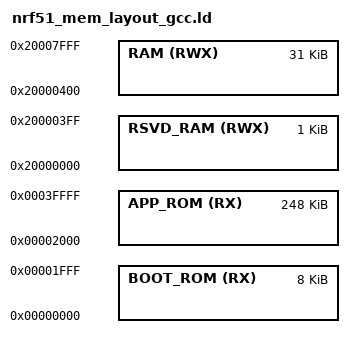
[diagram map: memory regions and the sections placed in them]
/*
 *    0x0000.0000 +----------------------------------------+    -----
 *                |                                        |      ^
 *                |          .system_isr_vectors           |      |
 *                |                                        |      |
 *                +----------------------------------------+      |
 *                |                                        |      |
 *                |           .boot_isr_vectors            |      |
 *                |                                        |      |
 *                +----------------------------------------+      |
 *                |                                        |      |
 *                |                                        |      |
 *                |                                        |      |
 *                |               .boot_text               |      |
 *                |                                        |      |
 *                |                                        |      |
 *                |                                        |      |
 *                +----------------------------------------+      |
 *                |                                        |      |
 *                |            .boot_data (LMA)            |      |
 *                |                                        |      |
 *                +----------------------------------------+      |
 *                |  /  /  /  /  /  /  /  /  /  /  /  /  / |      |
 *                | /  /  /  /  /  RESERVED /  /  /  /  /  |    FLASH
 *                |/  /  /  /  /  /  /  /  /  /  /  /  /  /|      |
 *    0x0000.2000 +----------------------------------------+      |
 *                |                                        |      |
 *                |            .app_isr_vectors            |      |
 *                |                                        |      |
 *                +----------------------------------------+      |
 *                |                                        |      |
 *                |                                        |      |
 *                |                                        |      |
 *                |               .app_text                |      |
 *                |                                        |      |
 *                |                                        |      |
 *                |                                        |      |
 *                +----------------------------------------+      |
 *                |                                        |      |
 *                |            .app_data (LMA)             |      |
 *                |                                        |      |
 *                +----------------------------------------+      |
 *                |  /  /  /  /  /  /  /  /  /  /  /  /  / |      |
 *                | /  /  /  /  /  RESERVED /  /  /  /  /  |      |
 *                |/  /  /  /  /  /  /  /  /  /  /  /  /  /|      v
 *    0x0004.0000 +----------------------------------------+    -----
 *                |  /  /  /  /  /  /  /  /  /  /  /  /  / |
 *                | /  /  /  /  /  RESERVED /  /  /  /  /  |
 *                |/  /  /  /  /  /  /  /  /  /  /  /  /  /|
 *    0x2000.0000 +----------------------------------------+    -----
 *                |              .pseudo_vtor              |      ^
 *    0x2000.0004 +----------------------------------------+      |
 *                |                                        |      |
 *                |              .*_data (VMA)             |      |
 *                |                                        |      |
 *                +----------------------------------------+      |
 *                |                                        |      |
 *                |                 .*_bss                 |      |
 *                |                                        |     RAM
 *                +----------------------------------------+      |
 *                |                                        |      |
 *                |                 .*_heap                |      |
 *                |                                        |      |
 *                +----------------------------------------+      |
 *                |                                        |      |
 *                |                .*_stack                |      |
 *                |                                        |      v
 *    0x2000.8000 +----------------------------------------+    -----
 */


_rom_start     = 0x00000000;
_rom_size      = 0x00040000; /* 256K */
_boot_rom_size = 0x00002000; /*   8K */
_ram_start     = 0x20000000;
_ram_size      = 0x00008000; /*  32K */
_ram_rsvd_size = 0x00000400; /*   1K */

MEMORY
{
    BOOT_ROM (RX)  : ORIGIN = _rom_start,                    LENGTH = _boot_rom_size
    APP_ROM  (RX)  : ORIGIN = (_rom_start + _boot_rom_size), LENGTH = (_rom_size - _boot_rom_size)
    RSVD_RAM (RWX) : ORIGIN = _ram_start,                    LENGTH = _ram_rsvd_size
    RAM      (RWX) : ORIGIN = (_ram_start + _ram_rsvd_size), LENGTH = (_ram_size - _ram_rsvd_size)
}
